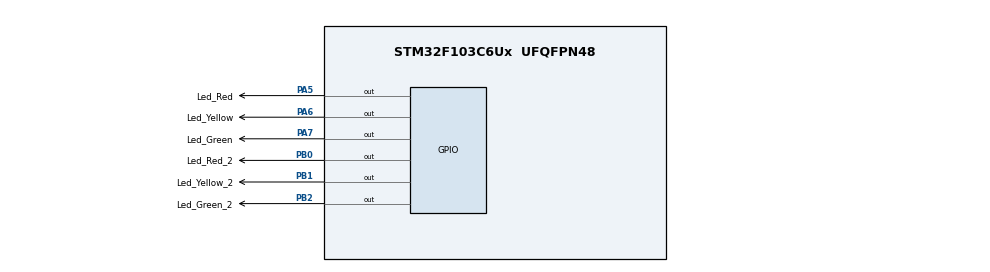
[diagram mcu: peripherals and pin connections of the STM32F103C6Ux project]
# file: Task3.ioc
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Mcu.Family=STM32F1
Mcu.Name=STM32F103C6Ux
Mcu.Package=UFQFPN48
NVIC.PriorityGroup=NVIC_PRIORITYGROUP_4
PA5.GPIO_Label=Led_Red
PA5.Signal=GPIO_Output
PA6.GPIO_Label=Led_Yellow
PA6.Signal=GPIO_Output
PA7.GPIO_Label=Led_Green
PA7.Signal=GPIO_Output
PB0.GPIO_Label=Led_Red_2
PB0.Signal=GPIO_Output
PB1.GPIO_Label=Led_Yellow_2
PB1.Signal=GPIO_Output
PB2.GPIO_Label=Led_Green_2
PB2.Signal=GPIO_Output
ProjectManager.HeapSize=0x200
ProjectManager.StackSize=0x400
ProjectManager.TargetToolchain=STM32CubeIDE
RCC.APB1Freq_Value=8000000
RCC.APB2Freq_Value=8000000
board=custom

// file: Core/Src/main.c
/* USER CODE BEGIN Header */
/**
  ******************************************************************************
  * @file           : main.c
  * @brief          : Main program body
  ******************************************************************************
  * @attention
  *
  * <h2><center>&copy; Copyright (c) 2022 STMicroelectronics.
  * All rights reserved.</center></h2>
  *
  * This software component is licensed by ST under BSD 3-Clause license,
  * the "License"; You may not use this file except in compliance with the
  * License. You may obtain a copy of the License at:
  *                        opensource.org/licenses/BSD-3-Clause
  *
  ******************************************************************************
  */
/* USER CODE END Header */
#include "main.h"

void SystemClock_Config(void);
static void MX_GPIO_Init(void);

int main(void)
{

  /* MCU Configuration--------------------------------------------------------*/

  /* Reset of all peripherals, Initializes the Flash interface and the Systick. */
  HAL_Init();

  /* Configure the system clock */
  SystemClock_Config();

  /* Initialize all configured peripherals */
  MX_GPIO_Init();

  /* Infinite loop */
  /* USER CODE BEGIN WHILE */
  int led_status = 1;
  int counter  = 3;

  while (1)
  {
	  counter = counter -1 ;  // 3, 2, 1, 0
   /* USER CODE END WHILE */
	  if(led_status == 1)
	  {
		  if(counter == 2 || counter ==1)
		  {
			  //Line 1,3 : Green On, Line 2,4: Red on
			 		  	 	  HAL_GPIO_WritePin ( LED_RED_Line1_GPIO_Port , LED_RED_Line1_Pin , RESET ); // red line 1 off
			 		  	 	  HAL_GPIO_WritePin ( LED_RED_Line3_GPIO_Port , LED_RED_Line3_Pin , RESET ); // red line 3 off
			 		  	 	  HAL_GPIO_WritePin ( Led_Yellow_1_GPIO_Port , Led_Yellow_1_Pin , RESET ); //yellow 1 off
			 		  		  HAL_GPIO_WritePin ( Led_Yellow_3_GPIO_Port , Led_Yellow_3_Pin , RESET ); //yellow 3 off
			 		  	 	  HAL_GPIO_WritePin ( Led_Green_1_GPIO_Port , Led_Green_1_Pin , SET ); // green 1,3 on
			 		  	 	  HAL_GPIO_WritePin ( Led_Green_3_GPIO_Port , Led_Green_3_Pin , SET );

			 		  	 	  HAL_GPIO_WritePin ( Led_Yellow_2_GPIO_Port , Led_Yellow_2_Pin , RESET );
			 		  	 	  HAL_GPIO_WritePin ( Led_Yellow_4_GPIO_Port , Led_Yellow_4_Pin , RESET );
			 		  	 	  HAL_GPIO_WritePin ( Led_Green_2_GPIO_Port , Led_Green_2_Pin , RESET );
			 		  	 	  HAL_GPIO_WritePin ( Led_Green_4_GPIO_Port , Led_Green_4_Pin , RESET );
			 		  	 	  HAL_GPIO_WritePin ( Led_Red_2_GPIO_Port , Led_Red_2_Pin , SET );
			 		  	 	  HAL_GPIO_WritePin ( Led_Red_4_GPIO_Port , Led_Red_4_Pin , SET );
		  }
		  if(counter == 0)
		  {
			  led_status = 2;
			  counter= 3;
		  }
	  }
	  if(led_status == 2)
	  {
		  counter = counter -1 ;  // 3-->0
		  if(counter == 2 || counter ==1 )
		  {
			  // Line 1,3 : Yellow On, Line 2,4: Red on
			  	 	 HAL_GPIO_WritePin ( Led_Red_2_GPIO_Port , Led_Red_2_Pin , SET );
			  	 	 HAL_GPIO_WritePin ( Led_Red_4_GPIO_Port , Led_Red_4_Pin , SET );
			  	 	 HAL_GPIO_WritePin ( Led_Yellow_2_GPIO_Port , Led_Yellow_2_Pin , RESET );
			  	     HAL_GPIO_WritePin ( Led_Yellow_4_GPIO_Port , Led_Yellow_4_Pin , RESET );
			  	 	 HAL_GPIO_WritePin ( Led_Green_2_GPIO_Port , Led_Green_2_Pin , RESET );
			  	 	 HAL_GPIO_WritePin ( Led_Green_4_GPIO_Port , Led_Green_4_Pin , RESET );

			  	 	  HAL_GPIO_WritePin ( Led_Green_1_GPIO_Port , Led_Green_1_Pin , RESET );
			  	 	  HAL_GPIO_WritePin ( Led_Green_3_GPIO_Port , Led_Green_3_Pin , RESET );
			  	 	  HAL_GPIO_WritePin ( Led_Red_1_GPIO_Port , Led_Red_1_Pin , RESET );
			  	 	  HAL_GPIO_WritePin ( Led_Red_3_GPIO_Port , Led_Red_3_Pin , RESET );
			  	 	  HAL_GPIO_WritePin ( Led_Yellow_1_GPIO_Port , Led_Yellow_1_Pin , SET );
			  	 	  HAL_GPIO_WritePin ( Led_Yellow_3_GPIO_Port , Led_Yellow_3_Pin , SET );
		  }
		  if(counter == 0)
		  {
			  led_status = 3;
			  counter= 3;
		  }
	  }
        if(led_status == 3)
        {
        	counter = counter -1 ;  // 3-->0
        	if(counter == 2|| counter==1 )
        	{
        		// Line 1,3 : Red On, Line 2,4: Green on
        			 	 HAL_GPIO_WritePin ( Led_Red_2_GPIO_Port , Led_Red_2_Pin , RESET );
        			 	 HAL_GPIO_WritePin ( Led_Red_4_GPIO_Port , Led_Red_4_Pin , RESET );
        			 	 HAL_GPIO_WritePin ( Led_Yellow_2_GPIO_Port , Led_Yellow_2_Pin , RESET );
        			 	 HAL_GPIO_WritePin ( Led_Yellow_4_GPIO_Port , Led_Yellow_4_Pin , RESET );
        			 	 HAL_GPIO_WritePin ( Led_Green_2_GPIO_Port , Led_Green_2_Pin , SET );
        			 	 HAL_GPIO_WritePin ( Led_Green_4_GPIO_Port , Led_Green_4_Pin , SET );

        			 	 HAL_GPIO_WritePin ( Led_Green_1_GPIO_Port , Led_Green_1_Pin , RESET );
        			 	 HAL_GPIO_WritePin ( Led_Green_3_GPIO_Port , Led_Green_3_Pin , RESET );
        			 	 HAL_GPIO_WritePin ( Led_Red_1_GPIO_Port , Led_Red_1_Pin , SET );
        			 	 HAL_GPIO_WritePin ( Led_Red_3_GPIO_Port , Led_Red_3_Pin , SET );
        			 	 HAL_GPIO_WritePin ( Led_Yellow_1_GPIO_Port , Led_Yellow_1_Pin , RESET );
        			 	 HAL_GPIO_WritePin ( Led_Yellow_3_GPIO_Port , Led_Yellow_3_Pin , RESET );
        	}
        	if(counter==0)
        	{
        		  led_status = 4;
        		  counter= 3;
        	}
        }
	     if(led_status == 4)
	     {
	    	 counter = counter -1;
	    	 if(counter == 2 || counter == 1)
	    	 {
	    		 // Line 1,3 : Red On, Line 2,4: Yellow on

	    			 	 HAL_GPIO_WritePin ( Led_Green_1_GPIO_Port , Led_Green_1_Pin , RESET );
	    			 	 HAL_GPIO_WritePin ( Led_Green_3_GPIO_Port , Led_Green_3_Pin , RESET );
	    			 	 HAL_GPIO_WritePin ( Led_Red_1_GPIO_Port , Led_Red_1_Pin , SET );
	    			 	 HAL_GPIO_WritePin ( Led_Red_3_GPIO_Port , Led_Red_3_Pin , SET );
	    			 	 HAL_GPIO_WritePin ( Led_Yellow_1_GPIO_Port , Led_Yellow_1_Pin , RESET );
	    			 	 HAL_GPIO_WritePin ( Led_Yellow_3_GPIO_Port , Led_Yellow_3_Pin , RESET );

	    				 HAL_GPIO_WritePin ( Led_Red_2_GPIO_Port , Led_Red_2_Pin , RESET );
	    				 HAL_GPIO_WritePin ( Led_Red_4_GPIO_Port , Led_Red_4_Pin , RESET );
	    				 HAL_GPIO_WritePin ( Led_Yellow_2_GPIO_Port , Led_Yellow_2_Pin , SET );
	    				 HAL_GPIO_WritePin ( Led_Yellow_4_GPIO_Port , Led_Yellow_4_Pin , SET );
	    				 HAL_GPIO_WritePin ( Led_Green_2_GPIO_Port , Led_Green_2_Pin , RESET );
	    				 HAL_GPIO_WritePin ( Led_Green_4_GPIO_Port , Led_Green_4_Pin , RESET );
	    	 }
	    	 if(counter == 0)
	    	 {
	    		  led_status = 1;
	    		  counter= 3;
	    	 }
	     }
		 HAL_Delay (1000);
  }
}

void SystemClock_Config(void)
{
  RCC_OscInitTypeDef RCC_OscInitStruct = {0};
  RCC_ClkInitTypeDef RCC_ClkInitStruct = {0};

  /** Initializes the RCC Oscillators according to the specified parameters
  * in the RCC_OscInitTypeDef structure.
  */
  RCC_OscInitStruct.OscillatorType = RCC_OSCILLATORTYPE_HSI;
  RCC_OscInitStruct.HSIState = RCC_HSI_ON;
  RCC_OscInitStruct.HSICalibrationValue = RCC_HSICALIBRATION_DEFAULT;
  RCC_OscInitStruct.PLL.PLLState = RCC_PLL_NONE;
  if (HAL_RCC_OscConfig(&RCC_OscInitStruct) != HAL_OK)
  {
    Error_Handler();
  }

  /** Initializes the CPU, AHB and APB buses clocks
  */
  RCC_ClkInitStruct.ClockType = RCC_CLOCKTYPE_HCLK|RCC_CLOCKTYPE_SYSCLK
                              |RCC_CLOCKTYPE_PCLK1|RCC_CLOCKTYPE_PCLK2;
  RCC_ClkInitStruct.SYSCLKSource = RCC_SYSCLKSOURCE_HSI;
  RCC_ClkInitStruct.AHBCLKDivider = RCC_SYSCLK_DIV1;
  RCC_ClkInitStruct.APB1CLKDivider = RCC_HCLK_DIV1;
  RCC_ClkInitStruct.APB2CLKDivider = RCC_HCLK_DIV1;

  if (HAL_RCC_ClockConfig(&RCC_ClkInitStruct, FLASH_LATENCY_0) != HAL_OK)
  {
    Error_Handler();
  }
}

static void MX_GPIO_Init(void)
{
  GPIO_InitTypeDef GPIO_InitStruct = {0};

  /* GPIO Ports Clock Enable */
  __HAL_RCC_GPIOA_CLK_ENABLE();

  /*Configure GPIO pin Output Level */
  HAL_GPIO_WritePin(GPIOA, Led_Red_1_Pin|Led_Yellow_1_Pin|Led_Green_1_Pin|Led_Red_2_Pin
                          |Led_Yellow_2_Pin|Led_Green_2_Pin|Led_Red_3_Pin|Led_Yellow_3_Pin
                          |Led_Green_3_Pin|Led_Red_4_Pin|Led_Yellow_4_Pin|Led_Green_4_Pin, GPIO_PIN_RESET);

  /*Configure GPIO pins : Led_Red_1_Pin Led_Yellow_1_Pin Led_Green_1_Pin Led_Red_2_Pin
                           Led_Yellow_2_Pin Led_Green_2_Pin Led_Red_3_Pin Led_Yellow_3_Pin
                           Led_Green_3_Pin Led_Red_4_Pin Led_Yellow_4_Pin Led_Green_4_Pin */
  GPIO_InitStruct.Pin = Led_Red_1_Pin|Led_Yellow_1_Pin|Led_Green_1_Pin|Led_Red_2_Pin
                          |Led_Yellow_2_Pin|Led_Green_2_Pin|Led_Red_3_Pin|Led_Yellow_3_Pin
                          |Led_Green_3_Pin|Led_Red_4_Pin|Led_Yellow_4_Pin|Led_Green_4_Pin;
  GPIO_InitStruct.Mode = GPIO_MODE_OUTPUT_PP;
  GPIO_InitStruct.Pull = GPIO_NOPULL;
  GPIO_InitStruct.Speed = GPIO_SPEED_FREQ_LOW;
  HAL_GPIO_Init(GPIOA, &GPIO_InitStruct);

}

void Error_Handler(void)
{
  __disable_irq();
  while (1)
  {
  }
}
